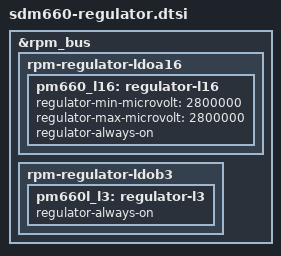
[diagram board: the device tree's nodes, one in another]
/* Copyright (c) 2016-2017, The Linux Foundation. All rights reserved.
 *
 * This program is free software; you can redistribute it and/or modify
 * it under the terms of the GNU General Public License version 2 and
 * only version 2 as published by the Free Software Foundation.
 *
 * This program is distributed in the hope that it will be useful,
 * but WITHOUT ANY WARRANTY; without even the implied warranty of
 * MERCHANTABILITY or FITNESS FOR A PARTICULAR PURPOSE.  See the
 * GNU General Public License for more details.
*/

&rpm_bus {
	rpm-regulator-ldoa16 {
		status = "okay";
		pm660_l16: regulator-l16 {
			regulator-min-microvolt = <2800000>;
			regulator-max-microvolt = <2800000>;
			status = "okay";
			regulator-always-on;
		};
	};
	rpm-regulator-ldob3 {
		pm660l_l3: regulator-l3 {
			regulator-always-on;
		};
	};
};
